# STM32F101 register map
File version: 1.2
CPU: CM3 r1p1, little endian, no MPU, no FPU, 4 interrupt priority bits
Registers are 32-bit, read-write, reset 0x0 unless marked. A register's access mark holds for its fields unless they carry their own. Offsets are from the block's base; [hi:lo] are bit positions; {n}, {i} and the like mark numbered series; 'fields as' and 'values as' point back to an identical list.

## FSMC — Flexible static memory controller
Base 0xA0000000
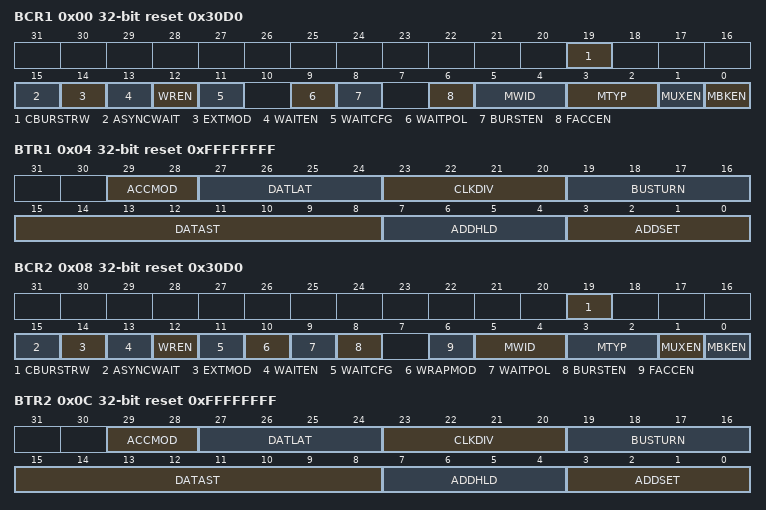
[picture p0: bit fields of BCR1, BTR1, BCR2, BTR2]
0x00 BCR1 reset 0x30D0 — SRAM/NOR-Flash chip-select control register 1
  [19] CBURSTRW, [15] ASYNCWAIT, [14] EXTMOD, [13] WAITEN, [12] WREN, [11] WAITCFG, [9] WAITPOL, [8] BURSTEN, [6] FACCEN, [5:4] MWID, [3:2] MTYP, [1] MUXEN, [0] MBKEN
0x04 BTR1 reset 0xFFFFFFFF — SRAM/NOR-Flash chip-select timing register 1
  [29:28] ACCMOD, [27:24] DATLAT, [23:20] CLKDIV, [19:16] BUSTURN, [15:8] DATAST, [7:4] ADDHLD, [3:0] ADDSET
0x08 BCR2 reset 0x30D0 — SRAM/NOR-Flash chip-select control register 2
  [19] CBURSTRW, [15] ASYNCWAIT, [14] EXTMOD, [13] WAITEN, [12] WREN, [11] WAITCFG, [10] WRAPMOD, [9] WAITPOL, [8] BURSTEN, [6] FACCEN, [5:4] MWID, [3:2] MTYP, [1] MUXEN, [0] MBKEN
0x0C BTR2 reset 0xFFFFFFFF — SRAM/NOR-Flash chip-select timing register 2
  fields as BTR1
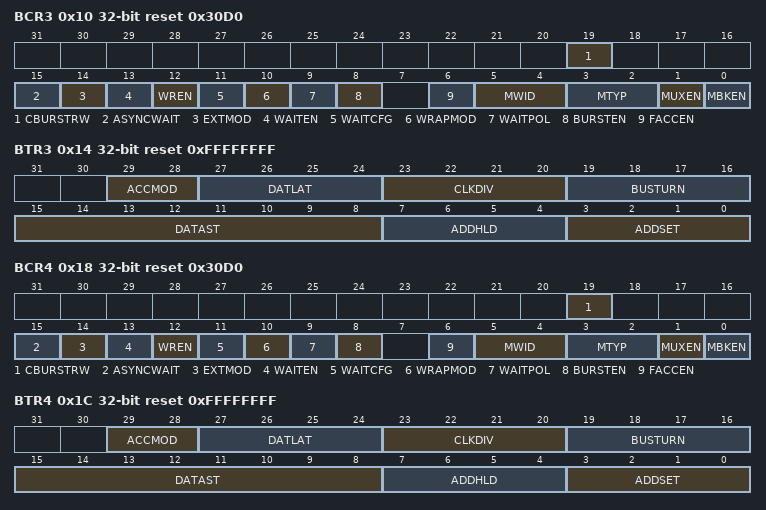
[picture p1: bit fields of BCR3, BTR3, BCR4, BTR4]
0x10 BCR3 reset 0x30D0 — SRAM/NOR-Flash chip-select control register 3
  fields as BCR2
0x14 BTR3 reset 0xFFFFFFFF — SRAM/NOR-Flash chip-select timing register 3
  fields as BTR1
0x18 BCR4 reset 0x30D0 — SRAM/NOR-Flash chip-select control register 4
  fields as BCR2
0x1C BTR4 reset 0xFFFFFFFF — SRAM/NOR-Flash chip-select timing register 4
  fields as BTR1
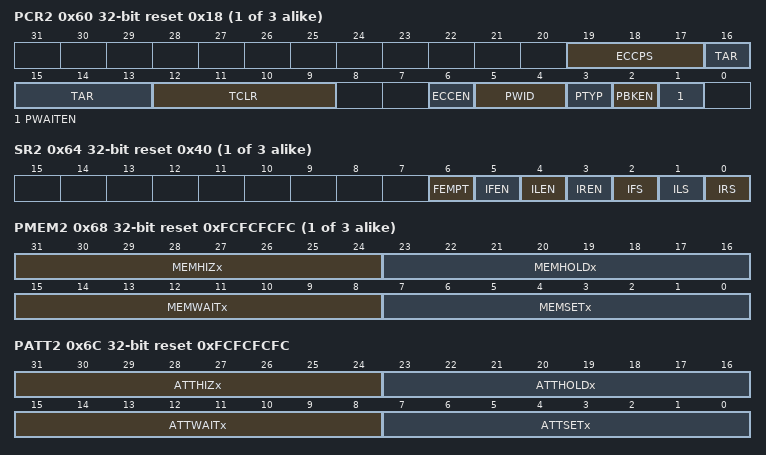
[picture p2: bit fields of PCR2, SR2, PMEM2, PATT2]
{0x20+0x20*i} PCR{i} reset 0x18 (i=2..4) — PC Card/NAND Flash control register {i}
  [19:17] ECCPS, [16:13] TAR, [12:9] TCLR, [6] ECCEN, [5:4] PWID, [3] PTYP, [2] PBKEN, [1] PWAITEN
{0x24+0x20*i} SR{i} access per field reset 0x40 (i=2..4) — FIFO status and interrupt register {i}
  [6] FEMPT ro, [5] IFEN rw, [4] ILEN rw, [3] IREN rw, [2] IFS rw, [1] ILS rw, [0] IRS rw
{0x28+0x20*i} PMEM{i} reset 0xFCFCFCFC (i=2..4) — Common memory space timing register {i}
  [31:24] MEMHIZx, [23:16] MEMHOLDx, [15:8] MEMWAITx, [7:0] MEMSETx
0x6C PATT2 reset 0xFCFCFCFC — Attribute memory space timing register 2
  [31:24] ATTHIZx — Attribute memory x databus HiZ time
  [23:16] ATTHOLDx — Attribute memory x hold time
  [15:8] ATTWAITx — Attribute memory x wait time
  [7:0] ATTSETx — Attribute memory x setup time
0x74 ECCR2 ro — ECC result register 2
  [31:0] ECCx — ECC result
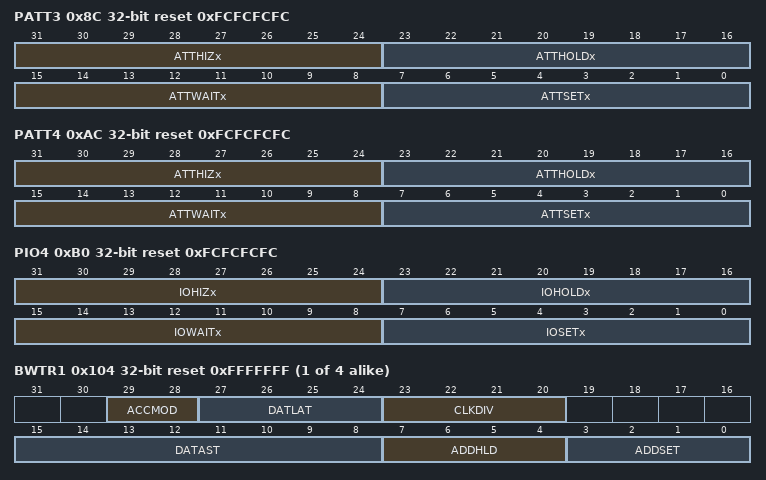
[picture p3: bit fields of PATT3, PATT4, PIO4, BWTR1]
0x8C PATT3 reset 0xFCFCFCFC — Attribute memory space timing register 3
  [31:24] ATTHIZx, [23:16] ATTHOLDx, [15:8] ATTWAITx, [7:0] ATTSETx
0x94 ECCR3 ro — ECC result register 3
  [31:0] ECCx
0xAC PATT4 reset 0xFCFCFCFC — Attribute memory space timing register 4
  [31:24] ATTHIZx, [23:16] ATTHOLDx, [15:8] ATTWAITx, [7:0] ATTSETx
0xB0 PIO4 reset 0xFCFCFCFC — I/O space timing register 4
  [31:24] IOHIZx, [23:16] IOHOLDx, [15:8] IOWAITx, [7:0] IOSETx
{0xFC+8i} BWTR{i} reset 0xFFFFFFF (i=1..4) — SRAM/NOR-Flash write timing registers {i}
  [29:28] ACCMOD, [27:24] DATLAT, [23:20] CLKDIV, [15:8] DATAST, [7:4] ADDHLD, [3:0] ADDSET

## PWR — Power control
Base 0x40007000
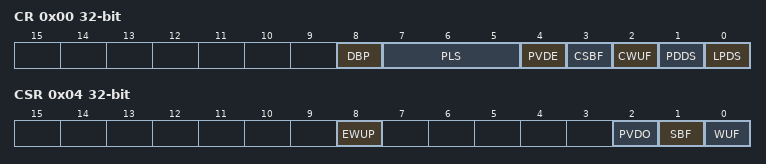
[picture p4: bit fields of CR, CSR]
0x00 CR — Power control register (PWR_CR)
  [8] DBP — Disable Backup Domain write protection
  [7:5] PLS — PVD Level Selection
  [4] PVDE — Power Voltage Detector Enable
  [3] CSBF — Clear STANDBY Flag
  [2] CWUF — Clear Wake-up Flag
  [1] PDDS — Power Down Deep Sleep
  [0] LPDS — Low Power Deep Sleep
0x04 CSR access per field — Power control register (PWR_CR)
  [8] EWUP rw — Enable WKUP pin
  [2] PVDO ro — PVD Output
  [1] SBF ro — STANDBY Flag
  [0] WUF ro — Wake-Up Flag

## GPIOA — General purpose I/O
Base 0x40010800
Same registers: GPIOB 0x40010C00, GPIOC 0x40011000, GPIOD 0x40011400, GPIOE 0x40011800, GPIOF 0x40011C00, GPIOG 0x40012000
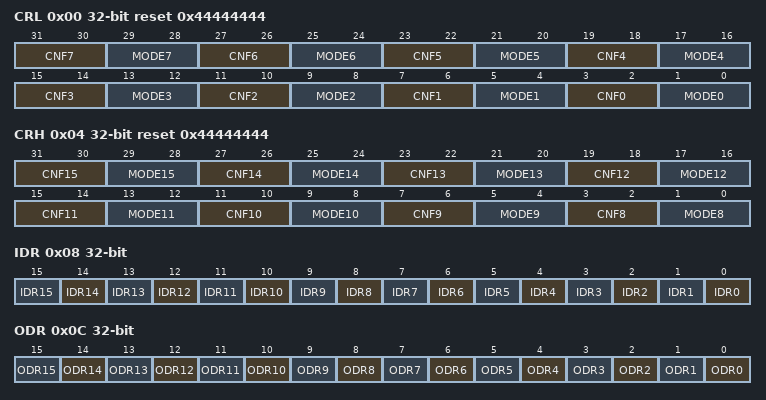
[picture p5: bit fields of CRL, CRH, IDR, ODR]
0x00 CRL reset 0x44444444 — Port configuration register low (GPIOn_CRL)
  [31:30] CNF7 — Port n.7 configuration bits
  [29:28] MODE7 — Port n.7 mode bits
  [27:26] CNF6 — Port n.6 configuration bits
  [25:24] MODE6 — Port n.6 mode bits
  [23:22] CNF5 — Port n.5 configuration bits
  [21:20] MODE5 — Port n.5 mode bits
  [19:18] CNF4 — Port n.4 configuration bits
  [17:16] MODE4 — Port n.4 mode bits
  [15:14] CNF3 — Port n.3 configuration bits
  [13:12] MODE3 — Port n.3 mode bits
  [11:10] CNF2 — Port n.2 configuration bits
  [9:8] MODE2 — Port n.2 mode bits
  [7:6] CNF1 — Port n.1 configuration bits
  [5:4] MODE1 — Port n.1 mode bits
  [3:2] CNF0 — Port n.0 configuration bits
  [1:0] MODE0 — Port n.0 mode bits
0x04 CRH reset 0x44444444 — Port configuration register high (GPIOn_CRL)
  [31:30] CNF15 — Port n.15 configuration bits
  [29:28] MODE15 — Port n.15 mode bits
  [27:26] CNF14 — Port n.14 configuration bits
  [25:24] MODE14 — Port n.14 mode bits
  [23:22] CNF13 — Port n.13 configuration bits
  [21:20] MODE13 — Port n.13 mode bits
  [19:18] CNF12 — Port n.12 configuration bits
  [17:16] MODE12 — Port n.12 mode bits
  [15:14] CNF11 — Port n.11 configuration bits
  [13:12] MODE11 — Port n.11 mode bits
  [11:10] CNF10 — Port n.10 configuration bits
  [9:8] MODE10 — Port n.10 mode bits
  [7:6] CNF9 — Port n.9 configuration bits
  [5:4] MODE9 — Port n.9 mode bits
  [3:2] CNF8 — Port n.8 configuration bits
  [1:0] MODE8 — Port n.8 mode bits
0x08 IDR ro — Port input data register (GPIOn_IDR)
  [n] IDR{n} (n=0..15) — Port input data
0x0C ODR — Port output data register (GPIOn_ODR)
  [n] ODR{n} (n=0..15) — Port output data
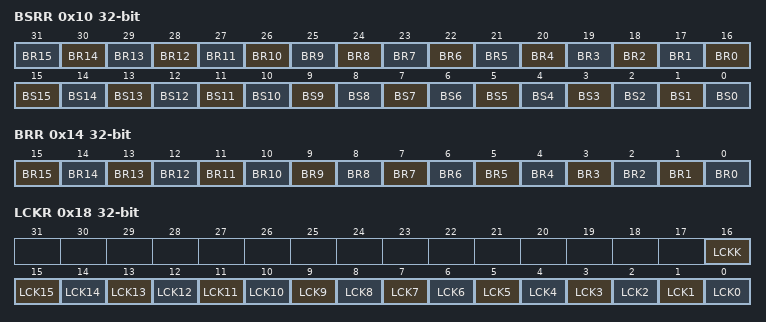
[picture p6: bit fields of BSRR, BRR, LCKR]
0x10 BSRR wo — Port bit set/reset register (GPIOn_BSRR)
  [n+16] BR{n} (n=0..15) — Reset bit {n}
  [n] BS{n} (n=3..15) — Set bit {n}
  [2] BS2 — Set bit 1
  [1] BS1 — Set bit 1
  [0] BS0 — Set bit 0
0x14 BRR wo — Port bit reset register (GPIOn_BRR)
  [n] BR{n} (n=3..15) — Reset bit {n}
  [2] BR2 — Reset bit 1
  [1] BR1 — Reset bit 1
  [0] BR0 — Reset bit 0
0x18 LCKR — Port configuration lock register
  [16] LCKK — Lock key
  [n] LCK{n} (n=0..15) — Port A Lock bit {n}
